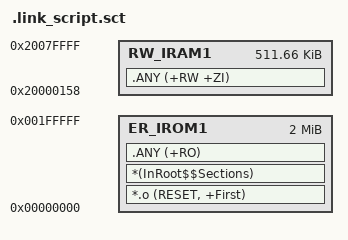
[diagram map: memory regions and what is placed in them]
#! armcc -E --cpu=Cortex-M4.fp -I .\mbed-os\targets\TARGET_Silicon_Labs\TARGET_EFM32\TARGET_EFM32GG11\device\TOOLCHAIN_ARM_STD
; *************************************************************
; *** Scatter-Loading Description File generated by uVision ***
; *************************************************************

#if !defined(MBED_APP_START)
  #define MBED_APP_START 0x00000000
#endif

#if !defined(MBED_APP_SIZE)
  #define MBED_APP_SIZE 0x00200000
#endif

LR_IROM1 MBED_APP_START MBED_APP_SIZE  {    ; load region size_region
  ER_IROM1 MBED_APP_START MBED_APP_SIZE  {  ; load address = execution address
   *.o (RESET, +First)
   *(InRoot$$Sections)
   .ANY (+RO)
  }
  RW_IRAM1 0x20000158 0x0007FEA8  {  ; RW data
   .ANY (+RW +ZI)
  }
}

